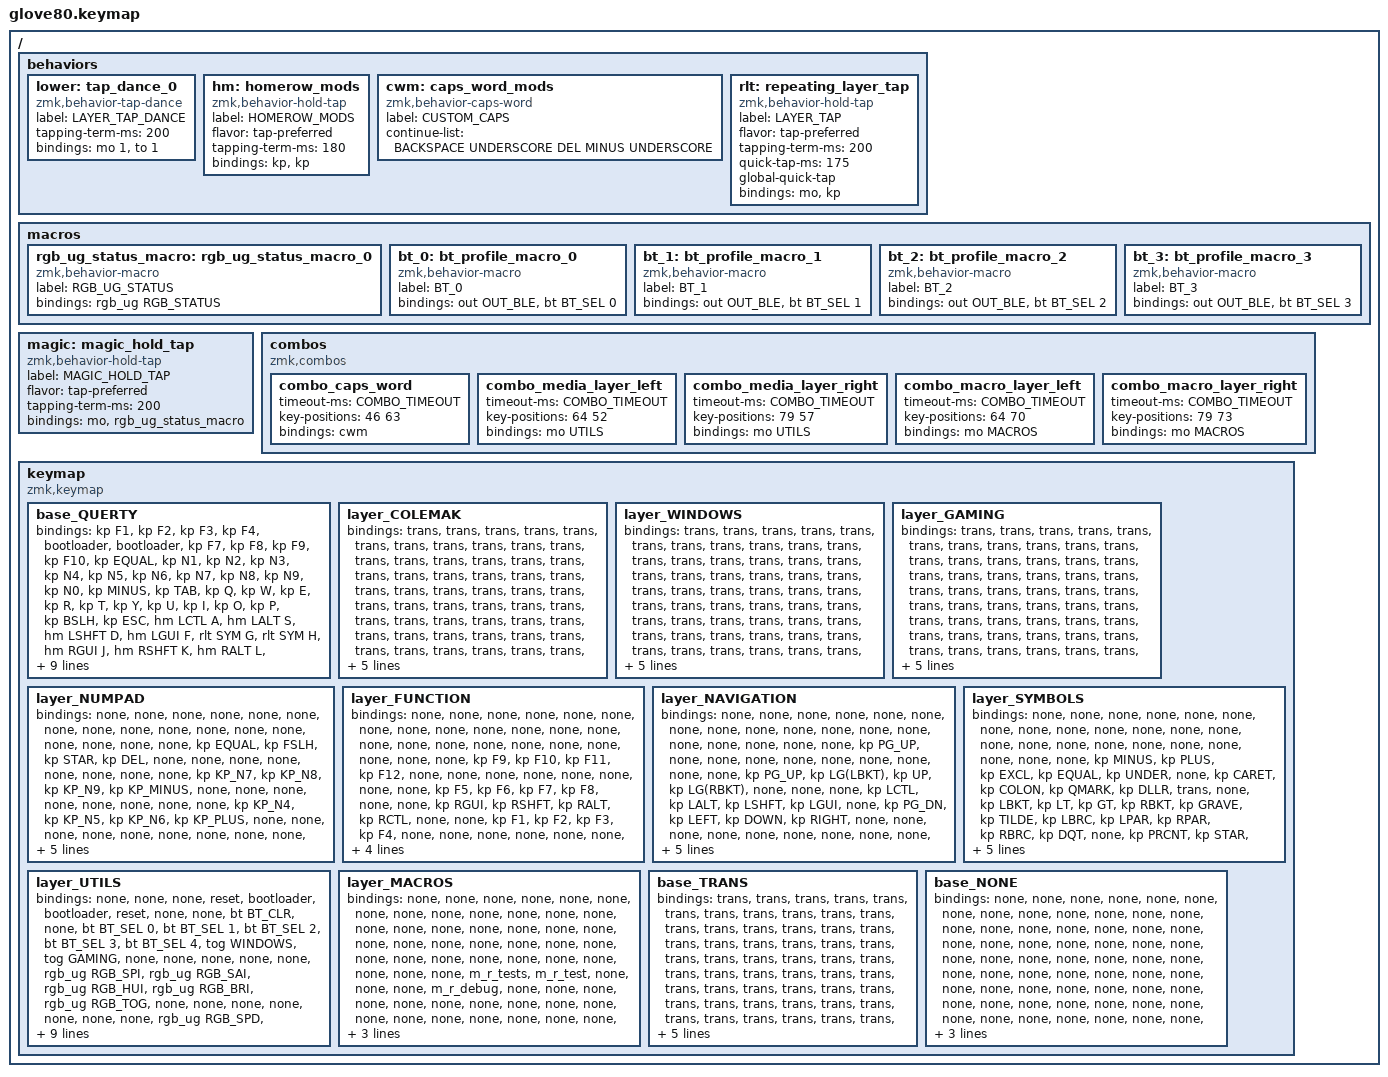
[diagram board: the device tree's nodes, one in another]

/*
 * Copyright (c) 2020 The ZMK Contributors
 * Copyright (c) 2022 Innaworks Development Limited, trading as MoErgo
 *
 * SPDX-License-Identifier: MIT
 */


/* THIS FILE WAS GENERATED BY GLOVE80 LAYOUT EDITOR
 *
 * This file was generated automatically. You may or may not want to
 * edit it directly.
 */

#include <behaviors.dtsi>
/* Include all behaviour includes needed by system behaviors/macros */
#include <dt-bindings/zmk/outputs.h>

/* Include behaviour includes needed by key binds - automatically generated */
#include <dt-bindings/zmk/keys.h>
#include <dt-bindings/zmk/bt.h>
#include <dt-bindings/zmk/rgb.h>
#include <dt-bindings/zmk/outputs.h>

#define QUERTY    0
#define COLEMAK   1
#define WINDOWS   2
#define GAMING    3
#define NUM       4
#define FUN       5
#define NAV       6
#define SYM       7
#define UTILS     8
#define MACROS    9

#define HYPER LS(LC(LA(LGUI)))

// Screen Shot to Clip Board
#define SCRSHT_CB LS(LC(LG(N3)))
// Screen Shot to File
#define SCRSHT_FI LS(LG(N3))
// Screen Selection to Clip Board
#define SLTSHT_CB LS(LC(LG(N4)))
// Screen Selection to File
#define SLTSHT_FI LS(LG(N4))
// Lock Screen
#define LOCK_SCR  LC(LG(Q))
#define SLEEP_DIS LS(LC(LA(LG(K))))

#define COMBO_TIMEOUT 300

/ {
    /* Glove80 system behavior & macros */
    behaviors {
        #include "macros.dtsi"

        // For the "layer" key, it would be nice to be able to use it as either a shift or a toggle.
        // Configure it as a tap dance, so the first tap (or hold) is a &mo and the second tap is a &to
        lower: tap_dance_0 {
            compatible = "zmk,behavior-tap-dance";
            label = "LAYER_TAP_DANCE";
            #binding-cells = <0>;
            tapping-term-ms = <200>;
            bindings = <&mo 1>, <&to 1>;
        };

        hm: homerow_mods {
            compatible = "zmk,behavior-hold-tap";
            label = "HOMEROW_MODS";
            #binding-cells = <2>;
            flavor = "tap-preferred";
            tapping-term-ms = <180>;
            bindings = <&kp>, <&kp>;
        };

        cwm: caps_word_mods {
            compatible = "zmk,behavior-caps-word";
            label = "CUSTOM_CAPS";
            #binding-cells = <0>;
            continue-list = <BACKSPACE UNDERSCORE DEL MINUS UNDERSCORE>;
        };

        rlt: repeating_layer_tap {
            compatible = "zmk,behavior-hold-tap";
            label = "LAYER_TAP";
            #binding-cells = <2>;
            flavor = "tap-preferred";
            tapping-term-ms = <200>;
            quick-tap-ms = <175>;
            global-quick-tap;
            bindings = <&mo>, <&kp>;
        };
    };

    macros {
        rgb_ug_status_macro: rgb_ug_status_macro_0 {
            label = "RGB_UG_STATUS";
            compatible = "zmk,behavior-macro";
            #binding-cells = <0>;
            bindings
                = <&rgb_ug RGB_STATUS>;
        };
    };

    macros {
        bt_0: bt_profile_macro_0 {
            label = "BT_0";
            compatible = "zmk,behavior-macro";
            #binding-cells = <0>;
            bindings
                = <&out OUT_BLE>,
                  <&bt BT_SEL 0>;
        };
    };

    macros {
        bt_1: bt_profile_macro_1 {
            label = "BT_1";
            compatible = "zmk,behavior-macro";
            #binding-cells = <0>;
            bindings
                = <&out OUT_BLE>,
                  <&bt BT_SEL 1>;
        };
    };

    macros {
        bt_2: bt_profile_macro_2 {
            label = "BT_2";
            compatible = "zmk,behavior-macro";
            #binding-cells = <0>;
            bindings
                = <&out OUT_BLE>,
                  <&bt BT_SEL 2>;
        };
    };

    macros {
        bt_3: bt_profile_macro_3 {
            label = "BT_3";
            compatible = "zmk,behavior-macro";
            #binding-cells = <0>;
            bindings
                = <&out OUT_BLE>,
                  <&bt BT_SEL 3>;
        };
    };

    magic: magic_hold_tap {
        compatible = "zmk,behavior-hold-tap";
        label = "MAGIC_HOLD_TAP";
        #binding-cells = <2>;
        flavor = "tap-preferred";
        tapping-term-ms = <200>;
        bindings = <&mo>, <&rgb_ug_status_macro>;
    };

    combos {
        compatible = "zmk,combos";
        combo_caps_word {
            timeout-ms = <COMBO_TIMEOUT>;
            key-positions = <46 63>;
            bindings = <&cwm>;
        };
        combo_media_layer_left {
            timeout-ms = <COMBO_TIMEOUT>;
            key-positions = <64 52>;
            bindings = <&mo UTILS>;
        };
        combo_media_layer_right {
            timeout-ms = <COMBO_TIMEOUT>;
            key-positions = <79 57>;
            bindings = <&mo UTILS>;
        };
        combo_macro_layer_left {
            timeout-ms = <COMBO_TIMEOUT>;
            key-positions = <64 70>;
            bindings = <&mo MACROS>;
        };
        combo_macro_layer_right {
            timeout-ms = <COMBO_TIMEOUT>;
            key-positions = <79 73>;
            bindings = <&mo MACROS>;
        };
    };


    keymap {
        compatible = "zmk,keymap";

// 00     01     02     03    04                                                                05     06     07    08     09
// 10     11     12     13    14     15                                                  16     17     18     19    20     21
// 22     23     24     25    26     27                                                  28     29     30     31    32     33
// 34     35     36     37    38     39                                                  40     41     42     43    44     45
// 46     47     48     49    50     51       52     53     54     55     56     57      58     59     60     61    62     63
// 64     65     66     67    68              69     70     71     72     73     74             75     76     77    78     79

        base_QUERTY {
            bindings = <
     &kp F1    &kp F2   &kp F3    &kp F4     &bootloader                                                                     &bootloader     &kp F7    &kp F8    &kp F9    &kp F10
  &kp EQUAL    &kp N1   &kp N2    &kp N3     &kp N4  &kp N5                                                                  &kp N6  &kp N7     &kp N8    &kp N9    &kp N0  &kp MINUS
    &kp TAB     &kp Q    &kp W     &kp E      &kp R   &kp T                                                                   &kp Y   &kp U      &kp I     &kp O     &kp P   &kp BSLH
    &kp ESC     &hm LCTL A  &hm LALT S  &hm LSHFT D  &hm LGUI F  &rlt SYM G                                                   &rlt SYM H    &hm RGUI J      &hm RSHFT K     &hm RALT L  &hm RCTRL SEMI    &kp SQT
    &kp LSHFT     &kp Z    &kp X     &kp C      &kp V   &kp B  &kp LGUI  &kp LALT    &rlt NUM HOME  &rlt FUN PG_UP  &kp RCTRL  &kp RGUI   &kp N   &kp M  &kp COMMA   &kp DOT  &kp FSLH  &kp RSHFT
    &mo UTILS  &kp GRAVE  &kp CAPS  &kp LEFT  &kp RIGHT        &kp BSPC  &rlt NAV DEL &hm HYPER END    &hm HYPER PG_DN  &kp ENTER &kp SPACE          &kp UP   &kp DOWN  &kp LBKT  &kp RBKT  &mo UTILS
            >;
        };

        layer_COLEMAK {
            bindings = <
&trans  &trans  &trans  &trans &trans                                                                     &trans  &trans  &trans  &trans &trans
&trans  &trans  &trans  &trans &trans  &trans                                                     &trans  &trans  &trans  &trans &trans  &trans
&trans  &trans  &trans  &trans &trans  &trans                                                     &trans  &trans  &trans  &trans &trans  &trans
&trans  &trans  &trans  &trans &trans  &trans                                                     &trans  &trans  &trans  &trans &trans  &trans
&trans  &trans  &trans  &trans &trans  &trans    &trans  &trans  &trans  &trans &trans  &trans    &trans  &trans  &trans  &trans &trans  &trans
&trans  &trans  &trans  &trans &trans            &trans  &trans  &trans  &trans &trans  &trans            &trans  &trans  &trans  &trans &trans
            >;
        };

        layer_WINDOWS {
            bindings = <
&trans  &trans  &trans  &trans &trans                                                                     &trans  &trans  &trans  &trans &trans
&trans  &trans  &trans  &trans &trans  &trans                                                     &trans  &trans  &trans  &trans &trans  &trans
&trans  &trans  &trans  &trans &trans  &trans                                                     &trans  &trans  &trans  &trans &trans  &trans
&trans  &trans  &trans  &trans &trans  &trans                                                     &trans  &trans  &trans  &trans &trans  &trans
&trans  &trans  &trans  &trans &trans  &trans    &trans  &trans  &trans  &trans &trans  &trans    &trans  &trans  &trans  &trans &trans  &trans
&trans  &trans  &trans  &trans &trans            &trans  &trans  &trans  &trans &trans  &trans            &trans  &trans  &trans  &trans &trans
            >;
        };

        layer_GAMING {
            bindings = <
&trans  &trans  &trans  &trans &trans                                                                     &trans  &trans  &trans  &trans &trans
&trans  &trans  &trans  &trans &trans  &trans                                                     &trans  &trans  &trans  &trans &trans  &trans
&trans  &trans  &trans  &trans &trans  &trans                                                     &trans  &trans  &trans  &trans &trans  &trans
&trans  &trans  &trans  &trans &trans  &trans                                                     &trans  &trans  &trans  &trans &trans  &trans
&trans  &trans  &trans  &trans &trans  &trans    &trans  &trans  &trans  &trans &trans  &trans    &trans  &trans  &trans  &trans &trans  &trans
&trans  &trans  &trans  &trans &trans            &trans  &trans  &trans  &trans &trans  &trans            &trans  &trans  &trans  &trans &trans
            >;
        };

        layer_NUMPAD {
            bindings = <
&none  &none  &none  &none &none                                                             &none  &none  &none  &none &none
&none  &none  &none  &none &none  &none                                               &none  &kp EQUAL  &kp FSLH    &kp STAR    &kp DEL       &none
&none  &none  &none  &none &none  &none                                               &none  &kp KP_N7  &kp KP_N8   &kp KP_N9   &kp KP_MINUS  &none
&none  &none  &none  &none &none  &none                                               &none  &kp KP_N4  &kp KP_N5   &kp KP_N6   &kp KP_PLUS  &none
&none  &none  &none  &none &none  &none    &none  &none  &none  &none &none  &none    &none  &kp KP_N1  &kp KP_N2   &kp KP_N3   &kp KP_ENTER  &none
&none  &none  &none  &none &none           &none  &none  &none  &none &none  &none           &kp KP_N0  &kp KP_N0   &kp DOT     &kp KP_ENTER &none
            >;
        };

        layer_FUNCTION {
            bindings = <
&none  &none  &none  &none &none                                                             &none  &none  &none  &none &none
&none  &none  &none  &none &none  &none                                               &none  &none  &none  &none &none  &none
&none  &kp F9  &kp F10  &kp F11  &kp F12  &none                                               &none  &none  &none  &none &none  &none
&none  &kp F5  &kp F6   &kp F7   &kp F8  &none                                               &none  &kp RGUI  &kp RSHFT &kp RALT &kp RCTL  &none
&none  &kp F1  &kp F2   &kp F3   &kp F4  &none    &none  &none  &none  &none &none  &none    &none  &none  &none  &none &none  &none
&none  &none  &none  &none &none           &none  &none  &none  &none &none  &none           &none  &none  &none  &none &none
            >;
        };

        layer_NAVIGATION {
            bindings = <
&none  &none  &none  &none &none                                                             &none  &none  &none  &none &none
&none  &none  &none  &none &none  &none                                               &none      &none         &kp PG_UP  &none            &none  &none
&none  &none  &none  &none &none  &none                                               &kp PG_UP  &kp LG(LBKT)  &kp UP     &kp LG(RBKT)     &none  &none
&none  &kp LCTL  &kp LALT  &kp LSHFT  &kp LGUI  &none                                 &kp PG_DN  &kp LEFT      &kp DOWN   &kp RIGHT        &none  &none
&none  &none  &none  &none &none  &none    &none  &none  &none  &none &none  &none    &none  &kp LG(LS(LBKT))  &kp PG_DN  &kp LG(LS(RBKT)) &none  &none
&none  &none  &none  &none &none           &none  &none  &none  &none &none  &none           &none             &none      &none            &none  &none
            >;
        };

        layer_SYMBOLS {
            bindings = <
&none  &none  &none  &none &none                                                                                &none      &none      &none      &none     &none
&none  &none  &none  &none &none  &none                                                              &none      &none      &none      &none      &none     &none
&none  &kp MINUS &kp PLUS &kp EXCL &kp EQUAL &kp UNDER                                               &none      &kp CARET  &kp COLON  &kp QMARK  &kp DLLR  &trans
&none  &kp LBKT  &kp LT  &kp GT &kp RBKT  &kp GRAVE                                                  &kp TILDE  &kp LBRC   &kp LPAR   &kp RPAR   &kp RBRC  &kp DQT
&none  &kp PRCNT  &kp STAR  &kp HASH  &kp AT  &trans      &none  &none  &none  &none &none  &none    &trans     &kp PIPE   &kp AMPS   &kp BSLH   &kp FSLH  &kp SQT
&none  &none  &none  &none &none                          &none  &none  &none  &none &none  &none               &none      &none      &none      &none     &none
            >;
        };

        layer_UTILS {
            bindings = <
&none  &none            &none            &reset           &bootloader                                                                                              &bootloader   &reset   &none   &none  &bt BT_CLR
&none  &bt BT_SEL 0  &bt BT_SEL 1  &bt BT_SEL 2  &bt BT_SEL 3   &bt BT_SEL 4                                                                               &tog WINDOWS  &tog GAMING   &none    &none   &none  &none
&none  &rgb_ug RGB_SPI  &rgb_ug RGB_SAI  &rgb_ug RGB_HUI  &rgb_ug RGB_BRI  &rgb_ug RGB_TOG                                                                 &none   &none         &none            &none   &none  &none
&none  &rgb_ug RGB_SPD  &rgb_ug RGB_SAD  &rgb_ug RGB_HUD  &rgb_ug RGB_BRD  &rgb_ug RGB_EFF                                                                 &none   &kp C_PREV    &kp C_PP         &kp C_NEXT   &none  &none
&none  &none            &none            &none            &none            &none             &none   &none  &none          &none   &none           &none   &none   &kp C_VOL_DN  &kp C_MUTE       &kp C_VOL_UP   &none  &none
&none  &none            &none            &none            &none                              &none   &kp LOCK_SCR  &none   &none   &kp SLEEP_DIS   &none           &none         &none    &none   &none  &none
            >;
        };

        layer_MACROS {
            bindings = <
&none  &none  &none  &none &none                                                              &none  &none       &none  &none  &none
&none  &none  &none  &none  &none  &none                                               &none  &none  &none       &none  &none  &none
&none  &none  &none  &none  &none  &none                                               &none  &none  &none       &none  &none  &none
&none  &none  &none  &m_r_tests &m_r_test  &none                                       &none  &none  &m_r_debug  &none  &none  &none
&none  &none  &none  &none  &none  &none    &none  &none  &none  &none &none  &none    &none  &none  &none       &none  &none  &none
&none  &none  &none  &none  &none           &none  &none  &none  &none &none  &none           &none  &none       &none  &none  &none
            >;
        };

        base_TRANS {
            bindings = <
&trans  &trans  &trans  &trans &trans                                                                     &trans  &trans  &trans  &trans &trans
&trans  &trans  &trans  &trans &trans  &trans                                                     &trans  &trans  &trans  &trans &trans  &trans
&trans  &trans  &trans  &trans &trans  &trans                                                     &trans  &trans  &trans  &trans &trans  &trans
&trans  &trans  &trans  &trans &trans  &trans                                                     &trans  &trans  &trans  &trans &trans  &trans
&trans  &trans  &trans  &trans &trans  &trans    &trans  &trans  &trans  &trans &trans  &trans    &trans  &trans  &trans  &trans &trans  &trans
&trans  &trans  &trans  &trans &trans            &trans  &trans  &trans  &trans &trans  &trans            &trans  &trans  &trans  &trans &trans
            >;
        };

        base_NONE {
            bindings = <
&none  &none  &none  &none &none                                                             &none  &none  &none  &none &none
&none  &none  &none  &none &none  &none                                               &none  &none  &none  &none &none  &none
&none  &none  &none  &none &none  &none                                               &none  &none  &none  &none &none  &none
&none  &none  &none  &none &none  &none                                               &none  &none  &none  &none &none  &none
&none  &none  &none  &none &none  &none    &none  &none  &none  &none &none  &none    &none  &none  &none  &none &none  &none
&none  &none  &none  &none &none           &none  &none  &none  &none &none  &none           &none  &none  &none  &none &none
            >;
        };
    };
};
